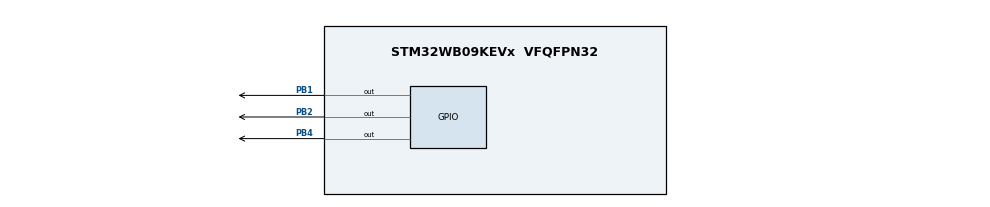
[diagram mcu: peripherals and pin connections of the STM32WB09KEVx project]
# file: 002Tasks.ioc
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Mcu.Family=STM32WB0
Mcu.Name=STM32WB09KEVx
Mcu.Package=VFQFPN32
NUCLEO-WB09KE.BUTTON=1
NUCLEO-WB09KE.BUTTON2=1
NUCLEO-WB09KE.BUTTON3=1
NUCLEO-WB09KE.LD1=true
NUCLEO-WB09KE.LD2=true
NUCLEO-WB09KE.LD3=true
NUCLEO-WB09KE.VCP=true
NVIC.TIM2_IRQn=true\:3\:0\:false\:false\:true\:false\:true\:true
NVIC.TimeBase=TIM2_IRQn
NVIC.TimeBaseIP=TIM2
PB1.Signal=GPIO_Output
PB2.Signal=GPIO_Output
PB4.Signal=GPIO_Output
ProjectManager.HeapSize=0x000
ProjectManager.StackSize=0xC00
ProjectManager.TargetToolchain=STM32CubeIDE
RCC.HSE_VALUE=32000000
RCC.HSI_VALUE=64000000
RCC.LSE_Timout=100
RCC.LSE_VALUE=32768
VP_MEMORYMAP_VS_MEMORYMAP.Mode=CurAppReg
VP_PWR_VS_SECSignals.Mode=Security/Privilege
VP_SYS_VS_tim2.Mode=TIM2
board=NUCLEO-WB09KE

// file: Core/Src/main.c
/* USER CODE BEGIN Header */
/**
  ******************************************************************************
  * @file           : main.c
  * @brief          : Main program body
  ******************************************************************************
  * @attention
  *
  * Copyright (c) 2025 STMicroelectronics.
  * All rights reserved.
  *
  * This software is licensed under terms that can be found in the LICENSE file
  * in the root directory of this software component.
  * If no LICENSE file comes with this software, it is provided AS-IS.
  *
  ******************************************************************************
  */
/* USER CODE END Header */
#include "main.h"

/* USER CODE BEGIN Includes */
#include "FreeRTOS.h"
#include "Task.h"
/* USER CODE END Includes */

/* USER CODE BEGIN PV */
#define DWT_CTRL (*(volatile uint32_t*) 0xE0001000)
/* USER CODE END PV */

void SystemClock_Config(void);
void PeriphCommonClock_Config(void);
static void MX_GPIO_Init(void);
/* USER CODE BEGIN PFP */
static void led_blue_handle(void* parameters);
static void led_green_handle(void* parameters);
static void led_red_handle(void* parameters);
/* USER CODE END PFP */

int main(void)
{

  /* USER CODE BEGIN 1 */
	TaskHandle_t task1_handler;
	TaskHandle_t task2_handler;
	TaskHandle_t task3_handler;
	BaseType_t status;
  /* USER CODE END 1 */

  /* MCU Configuration--------------------------------------------------------*/

  /* Reset of all peripherals, Initializes the Flash interface and the Systick. */
  HAL_Init();

  /* Configure the system clock */
  SystemClock_Config();

  /* Configure the peripherals common clocks */
  PeriphCommonClock_Config();

  /* Initialize all configured peripherals */
  MX_GPIO_Init();
  /* USER CODE BEGIN 2 */
  DWT_CTRL |= (1 << 0);

  SEGGER_SYSVIEW_Conf();

  SEGGER_SYSVIEW_Start();

  status = xTaskCreate(led_blue_handle, "Blue_LED", 128, NULL, 2, &task1_handler);
  configASSERT(status == pdPASS);

  status = xTaskCreate(led_green_handle, "Green_LED", 128, NULL, 2, &task2_handler);
  configASSERT(status == pdPASS);

  status = xTaskCreate(led_red_handle, "Red_LED", 128, NULL, 2, &task3_handler);
  configASSERT(status == pdPASS);
  // start the freeRTOS scheduler
  vTaskStartScheduler();
  /* USER CODE END 2 */

  /* Infinite loop */
  while (1)
  {

  }
}

void SystemClock_Config(void)
{
  RCC_ClkInitTypeDef RCC_ClkInitStruct = {0};

  /** Configure the SYSCLKSource and SYSCLKDivider
  */
  RCC_ClkInitStruct.SYSCLKSource = RCC_SYSCLKSOURCE_HSI;
  RCC_ClkInitStruct.SYSCLKDivider = RCC_RC64MPLL_DIV1;

  if (HAL_RCC_ClockConfig(&RCC_ClkInitStruct, FLASH_WAIT_STATES_1) != HAL_OK)
  {
    Error_Handler();
  }
}

void PeriphCommonClock_Config(void)
{
  RCC_PeriphCLKInitTypeDef PeriphClkInitStruct = {0};

  /** Initializes the peripherals clock
  */
  PeriphClkInitStruct.PeriphClockSelection = RCC_PERIPHCLK_SMPS;
  PeriphClkInitStruct.SmpsDivSelection = RCC_SMPSCLK_DIV4;

  if (HAL_RCCEx_PeriphCLKConfig(&PeriphClkInitStruct) != HAL_OK)
  {
    Error_Handler();
  }
}

static void MX_GPIO_Init(void)
{
  GPIO_InitTypeDef GPIO_InitStruct = {0};

  /* GPIO Ports Clock Enable */
  __HAL_RCC_GPIOB_CLK_ENABLE();

  /*Configure GPIO pin Output Level */
  HAL_GPIO_WritePin(GPIOB, GPIO_PIN_2|GPIO_PIN_1|GPIO_PIN_4, GPIO_PIN_RESET);

  /*Configure GPIO pins : PB2 PB1 PB4 */
  GPIO_InitStruct.Pin = GPIO_PIN_2|GPIO_PIN_1|GPIO_PIN_4;
  GPIO_InitStruct.Mode = GPIO_MODE_OUTPUT_PP;
  GPIO_InitStruct.Pull = GPIO_NOPULL;
  GPIO_InitStruct.Speed = GPIO_SPEED_FREQ_LOW;
  HAL_GPIO_Init(GPIOB, &GPIO_InitStruct);

  /**/
  HAL_PWREx_DisableGPIOPullUp(PWR_GPIO_B, PWR_GPIO_BIT_2|PWR_GPIO_BIT_1|PWR_GPIO_BIT_4);

  /**/
  HAL_PWREx_DisableGPIOPullDown(PWR_GPIO_B, PWR_GPIO_BIT_2|PWR_GPIO_BIT_1|PWR_GPIO_BIT_4);

}

/* USER CODE BEGIN 4 */
// LD1 - PB1 - Blue
// LD2 - PB4 - Green
// LD3 - PB2 - Red
static void led_blue_handle(void* parameters){
	while(1){
		SEGGER_SYSVIEW_PrintfTarget("Toggling Blue LED");
		HAL_GPIO_TogglePin(GPIOB, GPIO_PIN_1);
		HAL_Delay(1000);
	}
}

static void led_green_handle(void* parameters){

	while(1){
		SEGGER_SYSVIEW_PrintfTarget("Toggling Green LED");
		HAL_GPIO_TogglePin(GPIOB, GPIO_PIN_4);
		HAL_Delay(800);
	}
}

static void led_red_handle(void* parameters){
	while(1){
		SEGGER_SYSVIEW_PrintfTarget("Toggling Red LED");
		HAL_GPIO_TogglePin(GPIOB, GPIO_PIN_2);
		HAL_Delay(400);
	}
}
/* USER CODE END 4 */

void HAL_TIM_PeriodElapsedCallback(TIM_HandleTypeDef *htim)
{
  if (htim->Instance == TIM2)
  {
    HAL_IncTick();
  }
}

void Error_Handler(void)
{
  __disable_irq();
  while (1)
  {
  }
}
